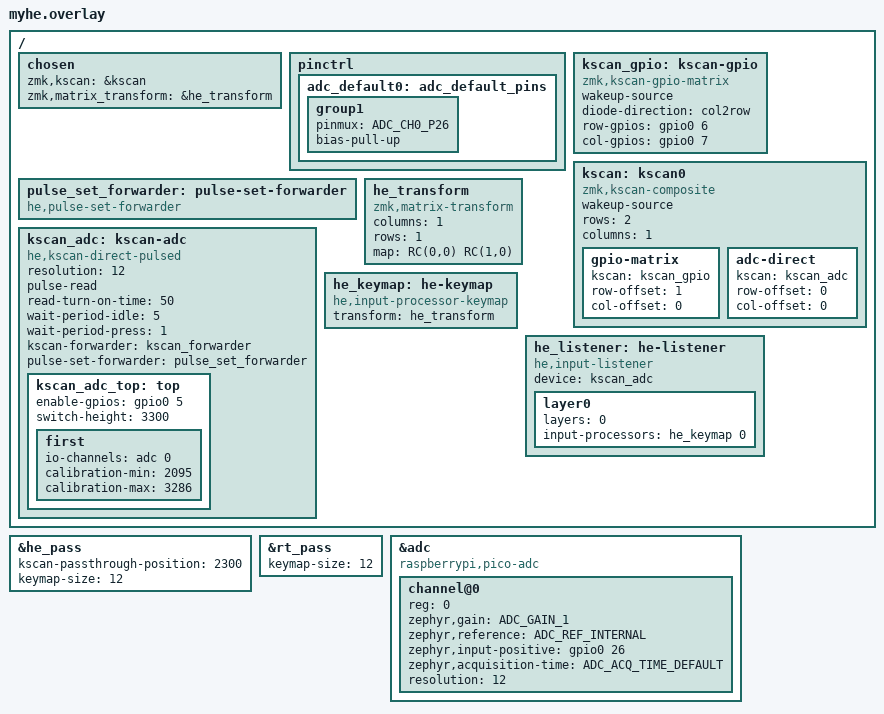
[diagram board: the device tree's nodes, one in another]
/*
* Copyright (c) 2025 Joomin97
*
* SPDX-License-Identifier: MIT
*/

#include <dt-bindings/zmk/matrix_transform.h>
#include <dt-bindings/input/input-event-codes.h>
#include <dt-bindings/pinctrl/rpi-pico-rp2040-pinctrl.h>
#include <input/he_processors.dtsi>

&he_pass {
    kscan-passthrough-position = <2300>;
    keymap-size = <12>;
};

&rt_pass{
    keymap-size = <12>;
};

/ {
    
    chosen {
        // zmk,physical-layout = &physical_layout0;
        zmk,kscan = &kscan;
        zmk,matrix_transform = &he_transform;
    };

    pinctrl {
        adc_default0: adc_default_pins {
            group1 {
                pinmux = <ADC_CH0_P26>;
                bias-pull-up;
            };
        };
    };

    kscan_gpio: kscan-gpio {
        compatible = "zmk,kscan-gpio-matrix";
        wakeup-source;

        diode-direction = "col2row";
        row-gpios
            = <&gpio0 6 (GPIO_ACTIVE_HIGH | GPIO_PULL_DOWN)>
            ;
        col-gpios
            = <&gpio0 7 GPIO_ACTIVE_HIGH>
            ;
    };

    kscan: kscan0 {
        compatible = "zmk,kscan-composite";
        wakeup-source;
        rows = <2>;
        columns = <1>;
        gpio-matrix {
            kscan = <&kscan_gpio>;
            row-offset = <1>;
            col-offset = <0>;
        };
        adc-direct {
            kscan = <&kscan_adc>;
            row-offset = <0>;
            col-offset = <0>;
        };
    };

    pulse_set_forwarder: pulse-set-forwarder {
        compatible = "he,pulse-set-forwarder";
    };

    kscan_adc: kscan-adc {
        compatible = "he,kscan-direct-pulsed";
        resolution = <12>;
        pulse-read;
        // calibrate;
        read-turn-on-time= <50>;
        wait-period-idle= <5>;
        wait-period-press= <1>;
        kscan-forwarder = <&kscan_forwarder>;
        pulse-set-forwarder= <&pulse_set_forwarder>;

        kscan_adc_top: top {
            enable-gpios= <&gpio0 5 (GPIO_ACTIVE_HIGH | GPIO_PULL_DOWN)>; // GP5
            switch-height = <3300>;

            first {
                io-channels = <&adc 0>;
                calibration-min = <2095>;
                calibration-max = <3286>;
            };
        };
    };

    he_transform: he_transform {// mapping of he sensors before going to kscan-composite but with he,input-processor-matrix-offset applied
        compatible = "zmk,matrix-transform";
        status= "okay";
        columns = <1>;
        rows = <1>;
        map = <
            RC(0,0)
            RC(1,0)
        >;
    };

    he_keymap: he-keymap {
        compatible = "he,input-processor-keymap";
        status= "okay";
        #input-processor-cells = <1>;
        transform = <&he_transform>;
    };

    he_listener: he-listener {
        compatible = "he,input-listener";
        status = "okay";
        device = <&kscan_adc>;

        layer0 {
            layers = <0>;
            input-processors = <&he_keymap 0>;
        };
    };

};

&adc {
    compatible = "raspberrypi,pico-adc";
    status = "okay";
    #io-channel-cells = <1>;

    #address-cells = <1>;
    #size-cells = <0>;

    channel@0 {
        reg = <0>;
        zephyr,gain = "ADC_GAIN_1";
        zephyr,reference = "ADC_REF_INTERNAL";
        zephyr,input-positive = <&gpio0 26>;
        zephyr,acquisition-time = <ADC_ACQ_TIME_DEFAULT>;
        resolution = <12>;
    };
};
